VERSION "0.0.00"

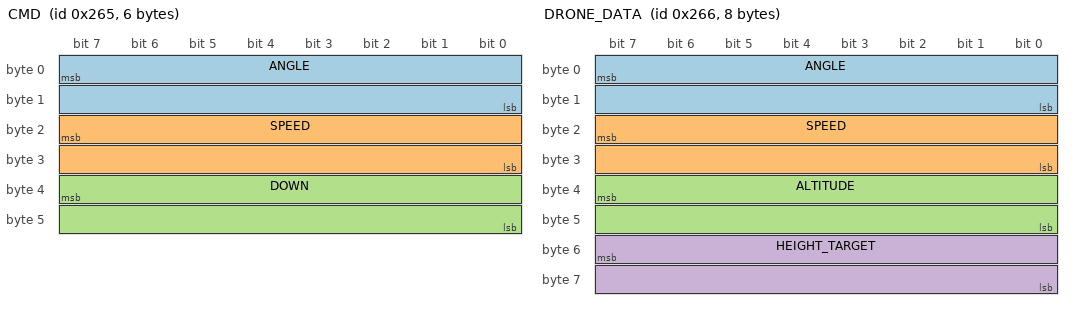
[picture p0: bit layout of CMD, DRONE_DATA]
BO_ 613 CMD: 6 XXX
  SG_ ANGLE : 7|16@0- (-0.1,0) [-3600|3600] "" XXX
  SG_ SPEED : 23|16@0+ (0.01,0) [0|10000] "" XXX
  SG_ DOWN : 39|16@0- (-0.01,0) [0|10000] "" XXX

BO_ 614 DRONE_DATA: 8 XXX
  SG_ ANGLE : 7|16@0- (-0.1,0) [-3600|3600] "" XXX
  SG_ SPEED : 23|16@0+ (0.01,0) [0|10000] "" XXX
  SG_ ALTITUDE : 39|16@0- (0.01,0) [0|10000] "" XXX
  SG_ HEIGHT_TARGET : 55|16@0+ (0.01,0) [0|10000] "" XXX

BO_ 615 DRONE_MODE: 2 XXX
  SG_ OFFBOARD : 7|8@0+ (1,0) [0|1] "" XXX
  SG_ ARMED : 15|8@0+ (1,0) [0|1] "" XXX
